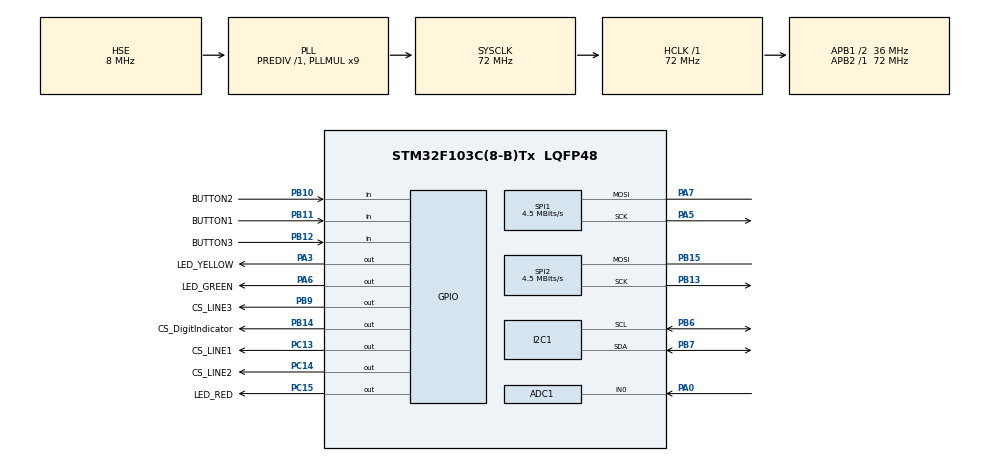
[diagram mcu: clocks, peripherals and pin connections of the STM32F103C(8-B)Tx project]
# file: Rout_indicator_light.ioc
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ADC1.Channel-1\#ChannelInjectedConversion=ADC_CHANNEL_0
ADC1.EnableInjectedConversion=ENABLE
ADC1.EnableRegularConversion=DISABLE
ADC1.InjNumberOfConversion=1
ADC1.InjectedOffset-1\#ChannelInjectedConversion=0
ADC1.Rank-1\#ChannelInjectedConversion=1
ADC1.SamplingTime-1\#ChannelInjectedConversion=ADC_SAMPLETIME_1CYCLE_5
ADC1.master=1
Mcu.Family=STM32F1
Mcu.Name=STM32F103C(8-B)Tx
Mcu.Package=LQFP48
NVIC.PriorityGroup=NVIC_PRIORITYGROUP_4
NVIC.TIM1_UP_IRQn=true\:0\:0\:false\:false\:true\:true\:true
PA0-WKUP.Signal=ADCx_IN0
PA13.Mode=Serial_Wire
PA13.Signal=SYS_JTMS-SWDIO
PA14.Mode=Serial_Wire
PA14.Signal=SYS_JTCK-SWCLK
PA3.GPIO_Label=LED_YELLOW
PA3.GPIO_PuPd=GPIO_PULLDOWN
PA3.PinState=GPIO_PIN_RESET
PA3.Signal=GPIO_Output
PA5.Mode=Simplex_Bidirectional_Master
PA5.Signal=SPI1_SCK
PA6.GPIO_Label=LED_GREEN
PA6.GPIO_PuPd=GPIO_PULLDOWN
PA6.PinState=GPIO_PIN_RESET
PA6.Signal=GPIO_Output
PA7.Mode=Simplex_Bidirectional_Master
PA7.Signal=SPI1_MOSI
PB10.GPIO_Label=BUTTON2
PB10.Signal=GPIO_Input
PB11.GPIO_Label=BUTTON1
PB11.Signal=GPIO_Input
PB12.GPIO_Label=BUTTON3
PB12.Signal=GPIO_Input
PB13.Mode=Simplex_Bidirectional_Master
PB13.Signal=SPI2_SCK
PB14.GPIO_Label=CS_DigitIndicator
PB14.GPIO_PuPd=GPIO_PULLUP
PB14.GPIO_Speed=GPIO_SPEED_FREQ_HIGH
PB14.PinState=GPIO_PIN_SET
PB14.Signal=GPIO_Output
PB15.Mode=Simplex_Bidirectional_Master
PB15.Signal=SPI2_MOSI
PB6.Mode=I2C
PB6.Signal=I2C1_SCL
PB7.Mode=I2C
PB7.Signal=I2C1_SDA
PB9.GPIO_Label=CS_LINE3
PB9.GPIO_PuPd=GPIO_PULLUP
PB9.GPIO_Speed=GPIO_SPEED_FREQ_HIGH
PB9.PinState=GPIO_PIN_SET
PB9.Signal=GPIO_Output
PC13-TAMPER-RTC.GPIO_Label=CS_LINE1
PC13-TAMPER-RTC.GPIO_PuPd=GPIO_PULLUP
PC13-TAMPER-RTC.GPIO_Speed=GPIO_SPEED_FREQ_HIGH
PC13-TAMPER-RTC.PinState=GPIO_PIN_SET
PC13-TAMPER-RTC.Signal=GPIO_Output
PC14-OSC32_IN.GPIO_Label=CS_LINE2
PC14-OSC32_IN.GPIO_PuPd=GPIO_PULLUP
PC14-OSC32_IN.GPIO_Speed=GPIO_SPEED_FREQ_HIGH
PC14-OSC32_IN.PinState=GPIO_PIN_SET
PC14-OSC32_IN.Signal=GPIO_Output
PC15-OSC32_OUT.GPIO_Label=LED_RED
PC15-OSC32_OUT.GPIO_PuPd=GPIO_PULLDOWN
PC15-OSC32_OUT.PinState=GPIO_PIN_RESET
PC15-OSC32_OUT.Signal=GPIO_Output
PD0-OSC_IN.Mode=HSE-External-Oscillator
PD0-OSC_IN.Signal=RCC_OSC_IN
PD1-OSC_OUT.Mode=HSE-External-Oscillator
PD1-OSC_OUT.Signal=RCC_OSC_OUT
ProjectManager.HeapSize=0x200
ProjectManager.StackSize=0x400
ProjectManager.TargetToolchain=STM32CubeIDE
RCC.ADCPresc=RCC_ADCPCLK2_DIV6
RCC.AHBFreq_Value=72000000
RCC.APB1CLKDivider=RCC_HCLK_DIV2
RCC.APB1Freq_Value=36000000
RCC.APB1TimFreq_Value=72000000
RCC.APB2Freq_Value=72000000
RCC.APB2TimFreq_Value=72000000
RCC.HCLKFreq_Value=72000000
RCC.PLLMUL=RCC_PLL_MUL9
RCC.PLLSourceVirtual=RCC_PLLSOURCE_HSE
RCC.SYSCLKFreq_VALUE=72000000
RCC.SYSCLKSource=RCC_SYSCLKSOURCE_PLLCLK
RCC.USBFreq_Value=72000000
SH.ADCx_IN0.0=ADC1_IN0,IN0
SPI1.BaudRatePrescaler=SPI_BAUDRATEPRESCALER_16
SPI1.CalculateBaudRate=4.5 MBits/s
SPI1.Direction=SPI_DIRECTION_1LINE
SPI1.Mode=SPI_MODE_MASTER
SPI1.VirtualType=VM_MASTER
SPI2.BaudRatePrescaler=SPI_BAUDRATEPRESCALER_8
SPI2.CalculateBaudRate=4.5 MBits/s
SPI2.Direction=SPI_DIRECTION_1LINE
SPI2.Mode=SPI_MODE_MASTER
SPI2.VirtualType=VM_MASTER
TIM1.Prescaler=1
VP_TIM1_VS_ClockSourceINT.Mode=Internal
board=custom

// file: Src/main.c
/* USER CODE BEGIN Header */
/**
  ******************************************************************************
  * @file           : main.c
  * @brief          : Main program body
  ******************************************************************************
  * @attention
  *
  * <h2><center>&copy; Copyright (c) 2021 STMicroelectronics.
  * All rights reserved.</center></h2>
  *
  * This software component is licensed by ST under BSD 3-Clause license,
  * the "License"; You may not use this file except in compliance with the
  * License. You may obtain a copy of the License at:
  *                        opensource.org/licenses/BSD-3-Clause
  *
  ******************************************************************************
  */
/* USER CODE END Header */
#include "main.h"

/* USER CODE BEGIN Includes */
#include "RIL_main.h"
/* USER CODE END Includes */

ADC_HandleTypeDef hadc1;

I2C_HandleTypeDef hi2c1;

SPI_HandleTypeDef hspi1;
SPI_HandleTypeDef hspi2;

TIM_HandleTypeDef htim1;

void SystemClock_Config(void);
static void MX_GPIO_Init(void);
static void MX_ADC1_Init(void);
static void MX_I2C1_Init(void);
static void MX_SPI1_Init(void);
static void MX_SPI2_Init(void);
static void MX_TIM1_Init(void);

int main(void)
{

  /* MCU Configuration--------------------------------------------------------*/

  /* Reset of all peripherals, Initializes the Flash interface and the Systick. */
  HAL_Init();

  /* Configure the system clock */
  SystemClock_Config();

  /* Initialize all configured peripherals */
  MX_GPIO_Init();
  MX_ADC1_Init();
  MX_I2C1_Init();
  MX_SPI1_Init();
  MX_SPI2_Init();
  MX_TIM1_Init();
  /* USER CODE BEGIN 2 */
  RIL_init();
  /* USER CODE END 2 */

  /* Infinite loop */
  /* USER CODE BEGIN WHILE */
  while (1)
  {
      RIL_run();
    /* USER CODE END WHILE */

  }
}

void SystemClock_Config(void)
{
  RCC_OscInitTypeDef RCC_OscInitStruct = {0};
  RCC_ClkInitTypeDef RCC_ClkInitStruct = {0};
  RCC_PeriphCLKInitTypeDef PeriphClkInit = {0};

  /** Initializes the RCC Oscillators according to the specified parameters
  * in the RCC_OscInitTypeDef structure.
  */
  RCC_OscInitStruct.OscillatorType = RCC_OSCILLATORTYPE_HSE;
  RCC_OscInitStruct.HSEState = RCC_HSE_ON;
  RCC_OscInitStruct.HSEPredivValue = RCC_HSE_PREDIV_DIV1;
  RCC_OscInitStruct.HSIState = RCC_HSI_ON;
  RCC_OscInitStruct.PLL.PLLState = RCC_PLL_ON;
  RCC_OscInitStruct.PLL.PLLSource = RCC_PLLSOURCE_HSE;
  RCC_OscInitStruct.PLL.PLLMUL = RCC_PLL_MUL9;
  if (HAL_RCC_OscConfig(&RCC_OscInitStruct) != HAL_OK)
  {
    Error_Handler();
  }
  /** Initializes the CPU, AHB and APB buses clocks
  */
  RCC_ClkInitStruct.ClockType = RCC_CLOCKTYPE_HCLK|RCC_CLOCKTYPE_SYSCLK
                              |RCC_CLOCKTYPE_PCLK1|RCC_CLOCKTYPE_PCLK2;
  RCC_ClkInitStruct.SYSCLKSource = RCC_SYSCLKSOURCE_PLLCLK;
  RCC_ClkInitStruct.AHBCLKDivider = RCC_SYSCLK_DIV1;
  RCC_ClkInitStruct.APB1CLKDivider = RCC_HCLK_DIV2;
  RCC_ClkInitStruct.APB2CLKDivider = RCC_HCLK_DIV1;

  if (HAL_RCC_ClockConfig(&RCC_ClkInitStruct, FLASH_LATENCY_2) != HAL_OK)
  {
    Error_Handler();
  }
  PeriphClkInit.PeriphClockSelection = RCC_PERIPHCLK_ADC;
  PeriphClkInit.AdcClockSelection = RCC_ADCPCLK2_DIV6;
  if (HAL_RCCEx_PeriphCLKConfig(&PeriphClkInit) != HAL_OK)
  {
    Error_Handler();
  }
}

static void MX_ADC1_Init(void)
{

  ADC_InjectionConfTypeDef sConfigInjected = {0};

  /** Common config
  */
  hadc1.Instance = ADC1;
  hadc1.Init.ScanConvMode = ADC_SCAN_DISABLE;
  hadc1.Init.ContinuousConvMode = DISABLE;
  hadc1.Init.DiscontinuousConvMode = DISABLE;
  hadc1.Init.ExternalTrigConv = ADC_SOFTWARE_START;
  hadc1.Init.DataAlign = ADC_DATAALIGN_RIGHT;
  hadc1.Init.NbrOfConversion = 1;
  if (HAL_ADC_Init(&hadc1) != HAL_OK)
  {
    Error_Handler();
  }
  /** Configure Injected Channel
  */
  sConfigInjected.InjectedChannel = ADC_CHANNEL_0;
  sConfigInjected.InjectedRank = ADC_INJECTED_RANK_1;
  sConfigInjected.InjectedNbrOfConversion = 1;
  sConfigInjected.InjectedSamplingTime = ADC_SAMPLETIME_1CYCLE_5;
  sConfigInjected.ExternalTrigInjecConv = ADC_INJECTED_SOFTWARE_START;
  sConfigInjected.AutoInjectedConv = DISABLE;
  sConfigInjected.InjectedDiscontinuousConvMode = DISABLE;
  sConfigInjected.InjectedOffset = 0;
  if (HAL_ADCEx_InjectedConfigChannel(&hadc1, &sConfigInjected) != HAL_OK)
  {
    Error_Handler();
  }

}

static void MX_I2C1_Init(void)
{

  hi2c1.Instance = I2C1;
  hi2c1.Init.ClockSpeed = 100000;
  hi2c1.Init.DutyCycle = I2C_DUTYCYCLE_2;
  hi2c1.Init.OwnAddress1 = 0;
  hi2c1.Init.AddressingMode = I2C_ADDRESSINGMODE_7BIT;
  hi2c1.Init.DualAddressMode = I2C_DUALADDRESS_DISABLE;
  hi2c1.Init.OwnAddress2 = 0;
  hi2c1.Init.GeneralCallMode = I2C_GENERALCALL_DISABLE;
  hi2c1.Init.NoStretchMode = I2C_NOSTRETCH_DISABLE;
  if (HAL_I2C_Init(&hi2c1) != HAL_OK)
  {
    Error_Handler();
  }

}

static void MX_SPI1_Init(void)
{

  /* SPI1 parameter configuration*/
  hspi1.Instance = SPI1;
  hspi1.Init.Mode = SPI_MODE_MASTER;
  hspi1.Init.Direction = SPI_DIRECTION_1LINE;
  hspi1.Init.DataSize = SPI_DATASIZE_8BIT;
  hspi1.Init.CLKPolarity = SPI_POLARITY_LOW;
  hspi1.Init.CLKPhase = SPI_PHASE_1EDGE;
  hspi1.Init.NSS = SPI_NSS_SOFT;
  hspi1.Init.BaudRatePrescaler = SPI_BAUDRATEPRESCALER_16;
  hspi1.Init.FirstBit = SPI_FIRSTBIT_MSB;
  hspi1.Init.TIMode = SPI_TIMODE_DISABLE;
  hspi1.Init.CRCCalculation = SPI_CRCCALCULATION_DISABLE;
  hspi1.Init.CRCPolynomial = 10;
  if (HAL_SPI_Init(&hspi1) != HAL_OK)
  {
    Error_Handler();
  }

}

static void MX_SPI2_Init(void)
{

  /* SPI2 parameter configuration*/
  hspi2.Instance = SPI2;
  hspi2.Init.Mode = SPI_MODE_MASTER;
  hspi2.Init.Direction = SPI_DIRECTION_1LINE;
  hspi2.Init.DataSize = SPI_DATASIZE_8BIT;
  hspi2.Init.CLKPolarity = SPI_POLARITY_LOW;
  hspi2.Init.CLKPhase = SPI_PHASE_1EDGE;
  hspi2.Init.NSS = SPI_NSS_SOFT;
  hspi2.Init.BaudRatePrescaler = SPI_BAUDRATEPRESCALER_8;
  hspi2.Init.FirstBit = SPI_FIRSTBIT_MSB;
  hspi2.Init.TIMode = SPI_TIMODE_DISABLE;
  hspi2.Init.CRCCalculation = SPI_CRCCALCULATION_DISABLE;
  hspi2.Init.CRCPolynomial = 10;
  if (HAL_SPI_Init(&hspi2) != HAL_OK)
  {
    Error_Handler();
  }

}

static void MX_TIM1_Init(void)
{

  TIM_ClockConfigTypeDef sClockSourceConfig = {0};
  TIM_MasterConfigTypeDef sMasterConfig = {0};

  htim1.Instance = TIM1;
  htim1.Init.Prescaler = 1;
  htim1.Init.CounterMode = TIM_COUNTERMODE_UP;
  htim1.Init.Period = 65535;
  htim1.Init.ClockDivision = TIM_CLOCKDIVISION_DIV1;
  htim1.Init.RepetitionCounter = 0;
  htim1.Init.AutoReloadPreload = TIM_AUTORELOAD_PRELOAD_DISABLE;
  if (HAL_TIM_Base_Init(&htim1) != HAL_OK)
  {
    Error_Handler();
  }
  sClockSourceConfig.ClockSource = TIM_CLOCKSOURCE_INTERNAL;
  if (HAL_TIM_ConfigClockSource(&htim1, &sClockSourceConfig) != HAL_OK)
  {
    Error_Handler();
  }
  sMasterConfig.MasterOutputTrigger = TIM_TRGO_RESET;
  sMasterConfig.MasterSlaveMode = TIM_MASTERSLAVEMODE_DISABLE;
  if (HAL_TIMEx_MasterConfigSynchronization(&htim1, &sMasterConfig) != HAL_OK)
  {
    Error_Handler();
  }

}

static void MX_GPIO_Init(void)
{
  GPIO_InitTypeDef GPIO_InitStruct = {0};

  /* GPIO Ports Clock Enable */
  __HAL_RCC_GPIOC_CLK_ENABLE();
  __HAL_RCC_GPIOD_CLK_ENABLE();
  __HAL_RCC_GPIOA_CLK_ENABLE();
  __HAL_RCC_GPIOB_CLK_ENABLE();

  /*Configure GPIO pin Output Level */
  HAL_GPIO_WritePin(GPIOC, CS_LINE1_Pin|CS_LINE2_Pin, GPIO_PIN_SET);

  /*Configure GPIO pin Output Level */
  HAL_GPIO_WritePin(LED_RED_GPIO_Port, LED_RED_Pin, GPIO_PIN_RESET);

  /*Configure GPIO pin Output Level */
  HAL_GPIO_WritePin(GPIOA, LED_YELLOW_Pin|LED_GREEN_Pin, GPIO_PIN_RESET);

  /*Configure GPIO pin Output Level */
  HAL_GPIO_WritePin(GPIOB, CS_DigitIndicator_Pin|CS_LINE3_Pin, GPIO_PIN_SET);

  /*Configure GPIO pins : CS_LINE1_Pin CS_LINE2_Pin */
  GPIO_InitStruct.Pin = CS_LINE1_Pin|CS_LINE2_Pin;
  GPIO_InitStruct.Mode = GPIO_MODE_OUTPUT_PP;
  GPIO_InitStruct.Pull = GPIO_PULLUP;
  GPIO_InitStruct.Speed = GPIO_SPEED_FREQ_HIGH;
  HAL_GPIO_Init(GPIOC, &GPIO_InitStruct);

  /*Configure GPIO pin : LED_RED_Pin */
  GPIO_InitStruct.Pin = LED_RED_Pin;
  GPIO_InitStruct.Mode = GPIO_MODE_OUTPUT_PP;
  GPIO_InitStruct.Pull = GPIO_PULLDOWN;
  GPIO_InitStruct.Speed = GPIO_SPEED_FREQ_LOW;
  HAL_GPIO_Init(LED_RED_GPIO_Port, &GPIO_InitStruct);

  /*Configure GPIO pins : LED_YELLOW_Pin LED_GREEN_Pin */
  GPIO_InitStruct.Pin = LED_YELLOW_Pin|LED_GREEN_Pin;
  GPIO_InitStruct.Mode = GPIO_MODE_OUTPUT_PP;
  GPIO_InitStruct.Pull = GPIO_PULLDOWN;
  GPIO_InitStruct.Speed = GPIO_SPEED_FREQ_LOW;
  HAL_GPIO_Init(GPIOA, &GPIO_InitStruct);

  /*Configure GPIO pins : BUTTON2_Pin BUTTON1_Pin BUTTON3_Pin */
  GPIO_InitStruct.Pin = BUTTON2_Pin|BUTTON1_Pin|BUTTON3_Pin;
  GPIO_InitStruct.Mode = GPIO_MODE_INPUT;
  GPIO_InitStruct.Pull = GPIO_NOPULL;
  HAL_GPIO_Init(GPIOB, &GPIO_InitStruct);

  /*Configure GPIO pins : CS_DigitIndicator_Pin CS_LINE3_Pin */
  GPIO_InitStruct.Pin = CS_DigitIndicator_Pin|CS_LINE3_Pin;
  GPIO_InitStruct.Mode = GPIO_MODE_OUTPUT_PP;
  GPIO_InitStruct.Pull = GPIO_PULLUP;
  GPIO_InitStruct.Speed = GPIO_SPEED_FREQ_HIGH;
  HAL_GPIO_Init(GPIOB, &GPIO_InitStruct);

}

void Error_Handler(void)
{
  __disable_irq();
  while (1)
  {
  }
}

/************************ (C) COPYRIGHT STMicroelectronics *****END OF FILE****/
